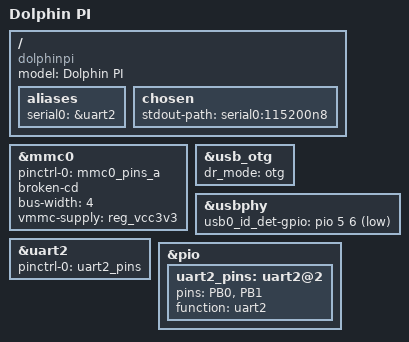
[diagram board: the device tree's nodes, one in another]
/dts-v1/;
#include "sun8i-v3s.dtsi"
#include "sunxi-common-regulators.dtsi"
#include <dt-bindings/input/input.h>
/ {
	model = "Dolphin PI";
	compatible = "dolphinpi", "allwinner,sun8i-v3s";

	aliases {
		serial0 = &uart2;
		/* ethernet0 = &emac; */
		
	};

	chosen {
		stdout-path = "serial0:115200n8";
		
		/*fb0: framebuffer@0 {
			compatible = "allwinner,simple-framebuffer", "simple-framebuffer";
			allwinner,pipeline = "de0-lcd0";
			clocks = <0x2 0x21 0x2 0x23 0x2 0x3f 0x2 0x40>;
			status = "disabled";
		}; */
	};
	
	/* leds {
		compatible = "gpio-leds";

		act_led {
			label = "act_led:green:usr";
			gpios = <&pio 1 2 GPIO_ACTIVE_HIGH>; /* PB2 */ /*
			linux,default-trigger = "mmc0";
			default-state = "off";
		};

	}; */
	
	/*soc {
		syscon: syscon@1c00000 {
			compatible = "allwinner,sun8i-v3s-system-controller",
			"syscon";
			reg = <0x01c00000 0x1000>;
		};


		emac: ethernet@1c30000 {
			compatible = "allwinner,sun8i-v3s-emac";
			syscon = <&syscon>;
			reg = <0x01c30000 0x104>;
			interrupts = <GIC_SPI 82 IRQ_TYPE_LEVEL_HIGH>;
			interrupt-names = "macirq";
			resets = <&ccu RST_BUS_EMAC>;
			reset-names = "stmmaceth";
			clocks = <&ccu CLK_BUS_EMAC>;
			clock-names = "stmmaceth";
			#address-cells = <1>;
			#size-cells = <0>;
			phy-handle = <&int_mii_phy>;
			phy-mode = "mii";
			status = "okay";
			allwinner,leds-active-high;
			
			mdio: mdio {
				#address-cells = <1>;
				#size-cells = <0>;
				compatible = "snps,dwmac-mdio";
			};

			mdio-mux {
				compatible = "mdio-mux", "allwinner,sun8i-h3-mdio-mux";
				#address-cells = <1>;
				#size-cells = <0>;

				mdio-parent-bus = <&mdio>;

				int_mdio: mdio@1 {
					compatible = "allwinner,sun8i-h3-mdio-internal";
					reg = <1>;
					#address-cells = <1>;
					#size-cells = <0>;
					
					int_mii_phy: ethernet-phy@1 {
						reg = <1>;
						clocks = <&ccu CLK_BUS_EPHY>;
						resets = <&ccu RST_BUS_EPHY>;
						phy-is-integrated;
					};
				};
			};
		};
	};*/
};

&mmc0 {
	pinctrl-0 = <&mmc0_pins_a>;
	pinctrl-names = "default";
	broken-cd;
	bus-width = <4>;
	vmmc-supply = <&reg_vcc3v3>;
	status = "okay";
};

&usb_otg {
	dr_mode = "otg";
	status = "okay";
};

&usbphy {
	/* pinctrl-0 = <&usb0_id_detect_pin>; */
	usb0_id_det-gpio = <&pio 5 6 GPIO_ACTIVE_LOW>;
	status = "okay";
};
/*
&i2c0 {
	pinctrl-0 = <&i2c0_pins>;
	pinctrl-names = "default";
	status = "okay";
};

&i2c1 {
	pinctrl-0 = <&i2c1_pins>;
	pinctrl-names = "default";
	status = "okay";
}; */

&uart2 {
	pinctrl-0 = <&uart2_pins>;
	pinctrl-names = "default";
	status = "okay";
};

/*
&spi0 {
	pinctrl-0 = <&spi0_pins>;
	pinctrl-names = "default";
	status = "okay";
	
};

&codec {
	allwinner,audio-routing = "Headphone", "HP", "Headphone", "HPCOM", "MIC1", "Mic", "Mic", "HBIAS";
	status = "okay";
};

&lradc {
	vref-supply = <&reg_vcc3v0>;
	status = "okay";

	button@200 {
		label = "Volume Up";
		linux,code = <KEY_VOLUMEUP>;
		channel = <0>;
		voltage = <200000>;
	};

	button@400 {
		label = "Volume Down";
		linux,code = <KEY_VOLUMEDOWN>;
		channel = <0>;
		voltage = <400000>;
	};

	button@600 {
		label = "Select";
		linux,code = <KEY_SELECT>;
		channel = <0>;
		voltage = <600000>;
	};

	button@800 {
		label = "Start";
		linux,code = <KEY_OK>;
		channel = <0>;
		voltage = <800000>;
	};
}; */

&pio {
	
	uart2_pins: uart2@2 {
		pins = "PB0", "PB1";
		function = "uart2";
	};

	/*
	i2c0_pins: i2c0 {
		pins = "PB6", "PB7";
		function = "i2c0";
	};

	i2c1_pins: i2c1 {
		pins = "PE21", "PE22";
		function = "i2c1";
	};
	
	usb0_id_detect_pin: usbid@0 {
		pins = "PF6";
		function = "gpio_in";
	};
	*/
};

